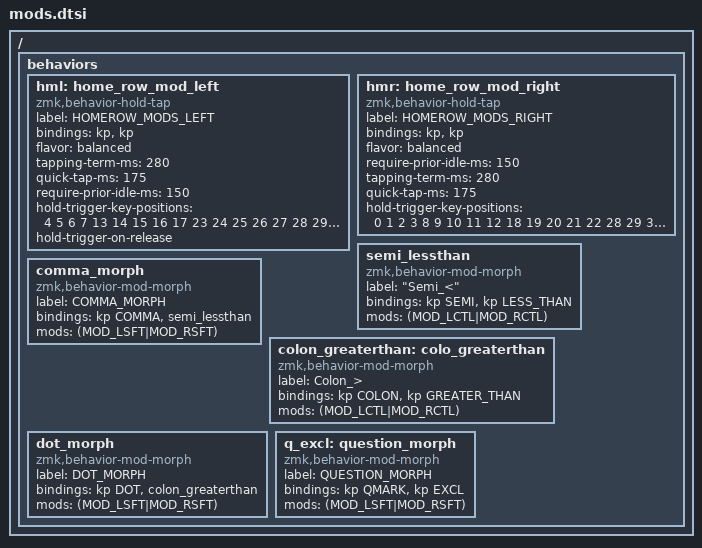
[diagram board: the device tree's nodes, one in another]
/ {
    behaviors {
        hml: home_row_mod_left {
            compatible = "zmk,behavior-hold-tap";
            label = "HOMEROW_MODS_LEFT";
            #binding-cells = <2>;
            bindings = <&kp>, <&kp>;

            flavor = "balanced";
            tapping-term-ms = <280>;
            quick-tap-ms = <175>;
            require-prior-idle-ms = <150>;
            hold-trigger-key-positions = <4 5 6 7 13 14 15 16 17 23 24 25 26 27 28 29 30 31 32 33>; 
            hold-trigger-on-release;
        };

        hmr: home_row_mod_right {
            compatible = "zmk,behavior-hold-tap";
            label = "HOMEROW_MODS_RIGHT";
            #binding-cells = <2>;
            bindings = <&kp>, <&kp>;

            flavor = "balanced";
            require-prior-idle-ms = <150>;
            tapping-term-ms = <280>;
            quick-tap-ms = <175>;
            hold-trigger-key-positions = <0 1 2 3 8 9 10 11 12 18 19 20 21 22 28 29 30 31 32 33>; 
        };


        // Tap: comma | Shift + tap: semicolon | Ctrl + shift + tap: <
        semi_lessthan: semi_lessthan {
            compatible = "zmk,behavior-mod-morph";
            label = "Semi_<";
            bindings = <&kp SEMI>, <&kp LESS_THAN>;

            #binding-cells = <0>;
            mods = <(MOD_LCTL|MOD_RCTL)>;
        };

        comma_morph: comma_morph {
            compatible = "zmk,behavior-mod-morph";
            label = "COMMA_MORPH";
            bindings = <&kp COMMA>, <&semi_lessthan>;

            #binding-cells = <0>;
            mods = <(MOD_LSFT|MOD_RSFT)>;
        };

        // Tap: dot | Shift + tap: colon | Ctrl + shift + tap: >
        colon_greaterthan: colo_greaterthan {
            compatible = "zmk,behavior-mod-morph";
            label = "Colon_>";
            bindings = <&kp COLON>, <&kp GREATER_THAN>;

            #binding-cells = <0>;
            mods = <(MOD_LCTL|MOD_RCTL)>;
        };

        dot_morph: dot_morph {
            compatible = "zmk,behavior-mod-morph";
            label = "DOT_MORPH";
            bindings = <&kp DOT>, <&colon_greaterthan>;

            #binding-cells = <0>;
            mods = <(MOD_LSFT|MOD_RSFT)>;
        };

        // Tap: ? | Shift + tap: ! 
        q_excl: question_morph {
            compatible = "zmk,behavior-mod-morph";
            label = "QUESTION_MORPH";
            bindings = <&kp QMARK>, <&kp EXCL>;

            #binding-cells = <0>;
            mods = <(MOD_LSFT|MOD_RSFT)>;
        };
    };
};
